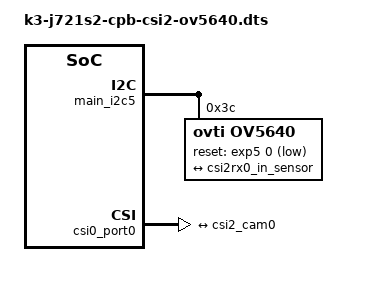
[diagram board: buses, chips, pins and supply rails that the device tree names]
// SPDX-License-Identifier: GPL-2.0
/*
 * Copyright (C) 2022 Texas Instruments Incorporated - https://www.ti.com/
 */

/dts-v1/;
/plugin/;

#include <dt-bindings/gpio/gpio.h>

/ {
	fragment@101 {
		target-path = "/";

		__overlay__ {
			clk_ov5640_fixed: ov5640-xclk {
				compatible = "fixed-clock";
				#clock-cells = <0>;
				clock-frequency = <25000000>;
			};
		};
	};
};

&main_i2c5 {
	#address-cells = <1>;
	#size-cells = <0>;

	ov5640: camera@3c {
		compatible = "ovti,ov5640";
		reg = <0x3c>;

		clocks = <&clk_ov5640_fixed>;
		clock-names = "xclk";
		reset-gpios = <&exp5 0 GPIO_ACTIVE_LOW>;

		port {
			csi2_cam0: endpoint {
				remote-endpoint = <&csi2rx0_in_sensor>;
				clock-lanes = <0>;
				data-lanes = <1 2>;
			};
		};
	};
};

&csi0_port0 {
	status = "okay";

	csi2rx0_in_sensor: endpoint {
		remote-endpoint = <&csi2_cam0>;
		bus-type = <4>;
		clock-lanes = <0>;
		data-lanes = <1 2>;
	};
};
